AUTOSAR XML (schema 4-2-2)
package /a01_types
  impl type idt_voltage: category=VALUE, base-type=float32
  impl type idt_duty: category=VALUE, base-type=float32
  app type adt_voltage: category=VALUE
  app type adt_duty: category=VALUE
package /a02_interfaces
  sender receiver interface sri_voltage
    data m_voltage: type=adt_voltage
  sender receiver interface sri_duty
    data m_dutyCycle: type=adt_duty
package /a05_arch
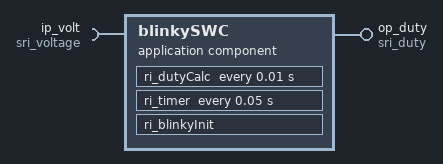
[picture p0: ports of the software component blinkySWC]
  application sw component type blinkySWC
    provide port op_duty: provided-interface=sri_duty
    require port ip_volt: required-interface=sri_voltage
    behavior IB_blinkySWC: data-type-mapping=DTMS_DataTypeMappingSet, handle-termination-and-restart=NO-SUPPORT
      timing event TE_10ms: start-on-event=ri_dutyCalc, period=0.01
      timing event TE_50ms: start-on-event=ri_timer, period=0.05
      runnable ri_blinkyInit
        data-write-access:
          access initDuty
      runnable ri_dutyCalc
        data-read-access:
          access ip_v: accessed-variable=ip_volt.m_voltage
        data-write-access:
          access op_duty
      runnable ri_timer
        data-read-access:
          access calcDuty
        data-write-access:
          access write_duty: accessed-variable=op_duty.m_dutyCycle
package /Cla_CommonUnits
  unit min: display-name=time: minutes, factor-si-to-unit=60
  13 x physical dimension:
    radpss: time-exp=-1
    radps: time-exp=-1
    rad: length-exp=0
    W: time-exp=-1
    J: length-exp=1
    N: mass-exp=1
    mpss: time-exp=-1
    mps: length-exp=1, time-exp=-1
    Nm: length-exp=1
    kgpm3: length-exp=-3, mass-exp=1
    kgps: mass-exp=1, time-exp=-1
    kgm2: length-exp=2, mass-exp=1
    m2: length-exp=2
  unit deg: display-name=Angle: Degrees, factor-si-to-unit=180
  unit rpm: display-name=Angular Speed: rev/min, factor-si-to-unit=30
  physical dimension WpK: temperature-exp=-1
  physical dimension JpK: temperature-exp=-1
  unit Nms: display-name=Damping: N-m/(rad/s)
  physical dimension m3: length-exp=3
  physical dimension V: current-exp=-1
  unit kW: display-name=Power: kilowatts, factor-si-to-unit=1000
  unit MW: display-name=Power: Megawatts, factor-si-to-unit=1000
  physical dimension Hz: time-exp=-1
  physical dimension Wpm2K: length-exp=-2, temperature-exp=-1
  unit mpspdegC: display-name=mps / degC - for ambient correction in ThermalModule
  unit degC: display-name=Temperature: Deg C
  physical dimension JpKgK: mass-exp=-1, temperature-exp=-1
  unit rev: display-name=Angular displacement: Revolutions, factor-si-to-unit=360
  physical dimension m3ps: length-exp=3, time-exp=-1
  physical dimension Pa: length-exp=-2
  unit kPa: display-name=Pressure or stress: Kilo Pascal, factor-si-to-unit=1000
  unit MPA: display-name=Pressure or stress: Mega Pascal, factor-si-to-unit=1000
  unit ms: display-name=milli second, factor-si-to-unit=1000
package /SIUnits
  7 x unit:
    m: display-name=metre
    s: display-name=second
    kg: display-name=kilogram
    mol: display-name=amount of chemical substance
    K: display-name=temperature
    A: display-name=current
    cd: display-name=luminous intensity
  physical dimension nounit: length-exp=0
package /a00_units
  physical dimension Hz: time-exp=-1
  unit kHz: display-name=Kilohertz, factor-si-to-unit=1000
  physical dimension V: length-exp=2, mass-exp=1, time-exp=-3, current-exp=-1
  unit pc: display-name=Percentage
package /a04_data
  range dutyCycle: phys null
  range minVoltage: phys  a00_units/V
  range voltage: phys null a00_units/V
package /a03_constants
  4 x sw systemconst, all with category=VALUE:
    minV
    maxV
    minDutyCyc
    maxDutyCyc
  4 x sw systemconstant value set:
    minV_ValueSet: sw-systemconst-value=sw-systemconst=minV
    maxV_ValueSet: sw-systemconst-value=sw-systemconst=maxV
    minDutyCyc_ValueSet: sw-systemconst-value{sw-systemconst=minDutyCyc, value=0}
    maxDutyCyc_ValueSet: sw-systemconst-value{sw-systemconst=maxDutyCyc, value=1}
